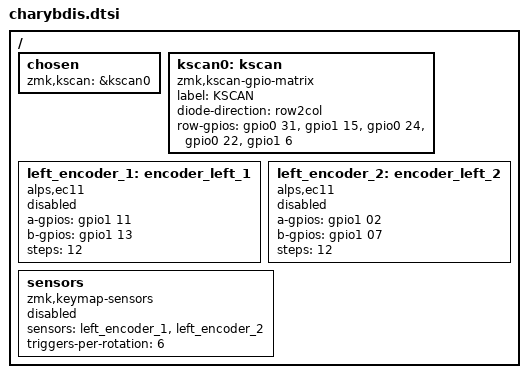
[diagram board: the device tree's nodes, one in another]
/*
 * Hardware common to the two halves. The dongle includes only
 * charybdis_layout.dtsi, since it has no matrix, encoders or LEDs.
 */

#include <dt-bindings/led/led.h>

#include "charybdis_layout.dtsi"

/ {
    chosen {
        zmk,kscan = &kscan0;
    };

	
    kscan0: kscan {
        compatible = "zmk,kscan-gpio-matrix";
        label = "KSCAN";

        diode-direction = "row2col";
		row-gpios
            = <&gpio0 31 GPIO_ACTIVE_HIGH>
            , <&gpio1 15 GPIO_ACTIVE_HIGH>
            , <&gpio0 24 GPIO_ACTIVE_HIGH>
	        , <&gpio0 22 GPIO_ACTIVE_HIGH>
	        , <&gpio1 6 GPIO_ACTIVE_HIGH>
            ;
    };

 left_encoder_1: encoder_left_1 {
        compatible = "alps,ec11";
        a-gpios = <&gpio1 11 (GPIO_ACTIVE_HIGH | GPIO_PULL_UP)>;
        b-gpios = <&gpio1 13 (GPIO_ACTIVE_HIGH | GPIO_PULL_UP)>;
        steps = <12>;
        status = "disabled";
    };

    left_encoder_2: encoder_left_2 {
        compatible = "alps,ec11";
      a-gpios = <&gpio1 02 (GPIO_ACTIVE_HIGH | GPIO_PULL_UP)>;
        b-gpios = <&gpio1 07 (GPIO_ACTIVE_HIGH | GPIO_PULL_UP)>;
        steps = <12>;
        status = "disabled";
    };

    sensors: sensors {
        compatible = "zmk,keymap-sensors";
        sensors = <&left_encoder_1 &left_encoder_2>;
		triggers-per-rotation = <6>;
        status = "disabled";
    };
};
